# CH32X035 register map
Vendor: WCH Ltd.; File version: 1.0
Registers are 32-bit, read-write, reset 0x0 unless marked. A register's access mark holds for its fields unless they carry their own. Offsets are from the block's base; [hi:lo] are bit positions; lines under a group give offsets from that group; {n}, {i} and the like mark numbered series.

## SPI1 — Serial peripheral interface
Base 0x40013000
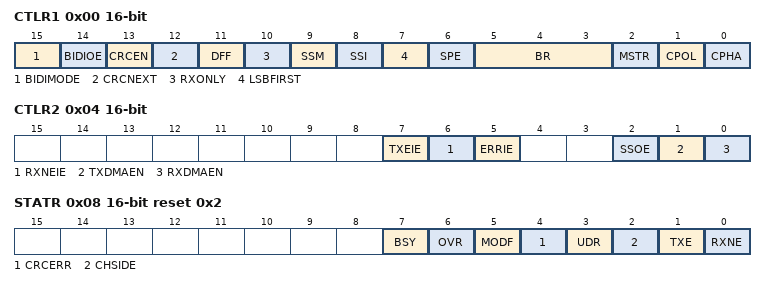
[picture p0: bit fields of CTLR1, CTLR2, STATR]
0x00 CTLR1 16-bit — control register 1
  [15] BIDIMODE — Bidirectional data mode enable
  [14] BIDIOE — Output enable in bidirectional mode
  [13] CRCEN — Hardware CRC calculation enable
  [12] CRCNEXT — CRC transfer next
  [11] DFF — Data frame format
  [10] RXONLY — Receive only
  [9] SSM — Software slave management
  [8] SSI — Internal slave select
  [7] LSBFIRST — Frame format
  [6] SPE — SPI enable
  [5:3] BR — Baud rate control
  [2] MSTR — Master selection
  [1] CPOL — Clock polarity
  [0] CPHA — Clock phase
0x04 CTLR2 16-bit — control register 2
  [7] TXEIE — Tx buffer empty interrupt enable
  [6] RXNEIE — RX buffer not empty interrupt enable
  [5] ERRIE — Error interrupt enable
  [2] SSOE — SS output enable
  [1] TXDMAEN — Tx buffer DMA enable
  [0] RXDMAEN — Rx buffer DMA enable
0x08 STATR 16-bit access per field reset 0x2 — status register
  [7] BSY ro — Busy flag
  [6] OVR rw — Overrun flag
  [5] MODF ro — Mode fault
  [4] CRCERR rw — CRC error flag
  [3] UDR ro — Underrun flag
  [2] CHSIDE ro — Channel side
  [1] TXE ro — Transmit buffer empty
  [0] RXNE ro — Receive buffer not empty
0x0C DATAR 16-bit — data register
  [15:0] DR — Data register
0x10 CRCR 16-bit reset 0x7 — CRCR polynomial register
  [15:0] CRCPOLY — CRC polynomial register
0x14 RCRCR 16-bit ro — RX CRC register
  [15:0] RXCRC
0x18 TCRCR 16-bit ro — send CRC register
  [15:0] TXCRC
0x24 HSCR 16-bit wo — high speed control register
  [0] HSRXEN — High speed mode read enable

## USART1 — Universal synchronous asynchronous receiver transmitter
Base 0x40013800
Same registers: USART2 0x40004400, USART3 0x40004800, USART4 0x40004C00
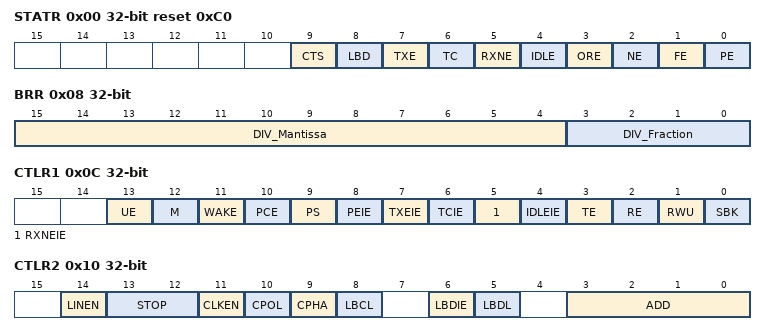
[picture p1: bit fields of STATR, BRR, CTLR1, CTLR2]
0x00 STATR access per field reset 0xC0 — Status register
  [9] CTS rw — CTS flag
  [8] LBD rw — LIN break detection flag
  [7] TXE ro — Transmit data register empty
  [6] TC rw — Transmission complete
  [5] RXNE rw — Read data register not empty
  [4] IDLE ro — IDLE line detected
  [3] ORE ro — Overrun error
  [2] NE ro — Noise error flag
  [1] FE ro — Framing error
  [0] PE ro — Parity error
0x04 DATAR — Data register
  [8:0] DR — Data value
0x08 BRR — Baud rate register
  [15:4] DIV_Mantissa — mantissa of USARTDIV
  [3:0] DIV_Fraction — fraction of USARTDIV
0x0C CTLR1 — Control register 1
  [13] UE — USART enable
  [12] M — Word length
  [11] WAKE — Wakeup method
  [10] PCE — Parity control enable
  [9] PS — Parity selection
  [8] PEIE — PE interrupt enable
  [7] TXEIE — TXE interrupt enable
  [6] TCIE — Transmission complete interrupt enable
  [5] RXNEIE — RXNE interrupt enable
  [4] IDLEIE — IDLE interrupt enable
  [3] TE — Transmitter enable
  [2] RE — Receiver enable
  [1] RWU — Receiver wakeup
  [0] SBK — Send break
0x10 CTLR2 — Control register 2
  [14] LINEN — LIN mode enable
  [13:12] STOP — STOP bits
  [11] CLKEN — Clock enable
  [10] CPOL — Clock polarity
  [9] CPHA — Clock phase
  [8] LBCL — Last bit clock pulse
  [6] LBDIE — LIN break detection interrupt enable
  [5] LBDL — lin break detection length
  [3:0] ADD — Address of the USART node
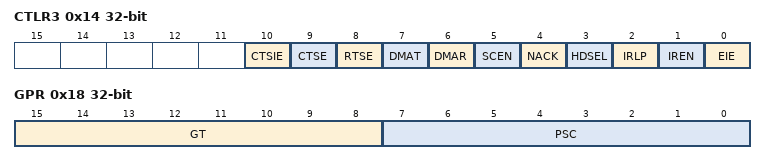
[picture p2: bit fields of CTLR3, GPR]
0x14 CTLR3 — Control register 3
  [10] CTSIE — CTS interrupt enable
  [9] CTSE — CTS enable
  [8] RTSE — RTS enable
  [7] DMAT — DMA enable transmitter
  [6] DMAR — DMA enable receiver
  [5] SCEN — Smartcard mode enable
  [4] NACK — Smartcard NACK enable
  [3] HDSEL — Half-duplex selection
  [2] IRLP — IrDA low-power
  [1] IREN — IrDA mode enable
  [0] EIE — Error interrupt enable
0x18 GPR — Guard time and prescaler register
  [15:8] GT — Guard time value
  [7:0] PSC — Prescaler value

## ADC — Analog to digital converter
Base 0x40012400
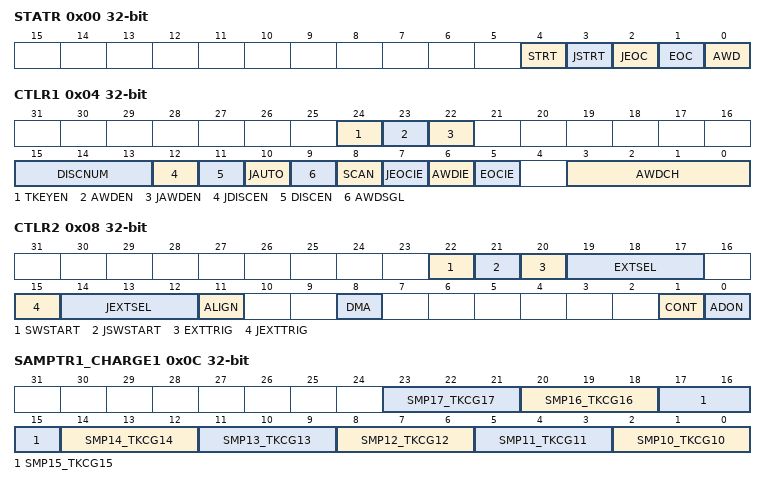
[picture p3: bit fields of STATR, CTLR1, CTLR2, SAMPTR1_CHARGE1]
0x00 STATR — status register
  [4] STRT — Regular channel start flag
  [3] JSTRT — Injected channel start flag
  [2] JEOC — Injected channel end of conversion
  [1] EOC — Regular channel end of conversion
  [0] AWD — Analog watchdog flag
0x04 CTLR1 — control register 1
  [24] TKEYEN — TKEY enable, including TKEY_F and TKEY_V
  [23] AWDEN — Analog watchdog enable on regular channels
  [22] JAWDEN — Analog watchdog enable on injected channels
  [15:13] DISCNUM — Discontinuous mode channel count
  [12] JDISCEN — Discontinuous mode on injected channels
  [11] DISCEN — Discontinuous mode on regular channels
  [10] JAUTO — Automatic injected group conversion
  [9] AWDSGL — Enable the watchdog on a single channel in scan mode
  [8] SCAN — Scan mode enable
  [7] JEOCIE — Interrupt enable for injected channels
  [6] AWDIE — Analog watchdog interrupt enable
  [5] EOCIE — Interrupt enable for EOC
  [3:0] AWDCH — Analog watchdog channel select bits
0x08 CTLR2 — control register 2
  [22] SWSTART — Start conversion of regular channels
  [21] JSWSTART — Start conversion of injected channels
  [20] EXTTRIG — External trigger conversion mode for regular channels
  [19:17] EXTSEL — External event select for regular group
  [15] JEXTTRIG — External trigger conversion mode for injected channels
  [14:12] JEXTSEL — External event select for injected group
  [11] ALIGN — Data alignment
  [8] DMA — Direct memory access mode
  [1] CONT — Continuous conversion
  [0] ADON — A/D converter ON / OFF
0x0C SAMPTR1_CHARGE1 — sample time register 1/TKEYx_CHARGE1
  [3n-28:3n-30] SMP{n}_TKCG{n} (n=10..17) — Channel {n} sample time selection
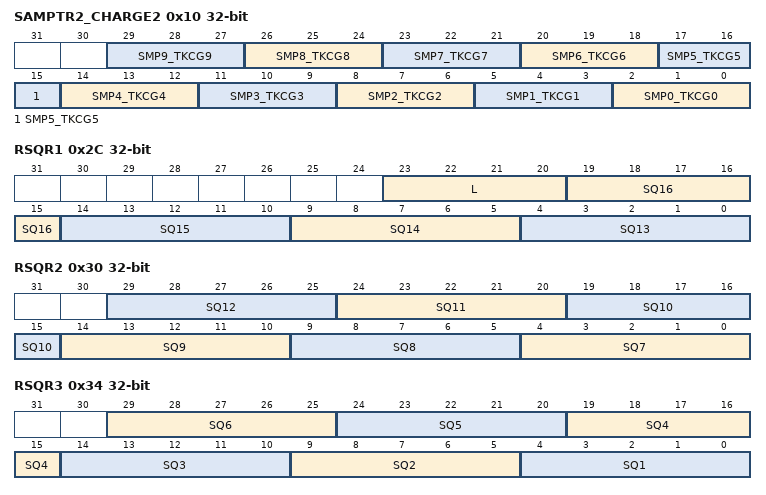
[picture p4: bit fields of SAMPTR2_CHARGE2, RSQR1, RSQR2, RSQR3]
0x10 SAMPTR2_CHARGE2 — sample time register 2/TKEYx_CHARGE2
  [3n+2:3n] SMP{n}_TKCG{n} (n=0..9) — Channel {n} sample time selection
{0x10+4i} IOFR{i} (i=1..4) — injected channel data offset register x
  [11:0] JOFFSET{i} — Data offset for injected channel x
0x24 WDHTR — watchdog higher threshold register
  [11:0] HT — Analog watchdog higher threshold
0x28 WDLTR — watchdog lower threshold register
  [11:0] LT — Analog watchdog lower threshold
0x2C RSQR1 — regular sequence register 1
  [23:20] L — Regular channel sequence length
  [5n-61:5n-65] SQ{n} (n=13..16) — {n}th conversion in regular sequence
0x30 RSQR2 — regular sequence register 2
  [5n-31:5n-35] SQ{n} (n=7..12) — {n}th conversion in regular sequence
0x34 RSQR3 — regular sequence register 3
  [29:25] SQ6 — 6th conversion in regular sequence
  [24:20] SQ5 — 5th conversion in regular sequence
  [19:15] SQ4 — 4th conversion in regular sequence
  [14:10] SQ3 — 3rd conversion in regular sequence
  [9:5] SQ2 — 2nd conversion in regular sequence
  [4:0] SQ1 — 1st conversion in regular sequence
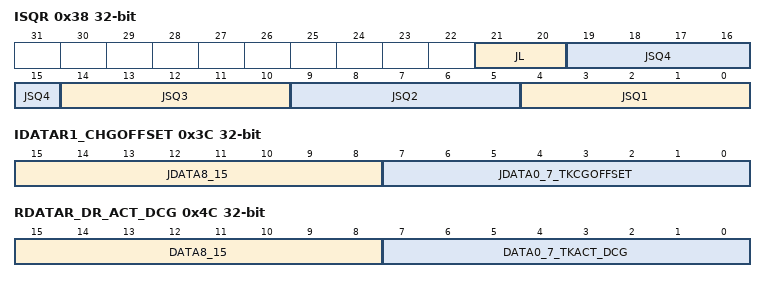
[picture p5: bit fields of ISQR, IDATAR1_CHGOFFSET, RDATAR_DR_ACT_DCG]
0x38 ISQR — injected sequence register
  [21:20] JL — Injected sequence length
  [19:15] JSQ4 — 4th conversion in injected sequence
  [14:10] JSQ3 — 3rd conversion in injected sequence
  [9:5] JSQ2 — 2nd conversion in injected sequence
  [4:0] JSQ1 — 1st conversion in injected sequence
0x3C IDATAR1_CHGOFFSET ro — injected data register x_Charge data offset for injected channel x/TKEYx_CHGOFFSET
  [15:8] JDATA8_15 — Injected data
  [7:0] JDATA0_7_TKCGOFFSET — Injected data_Touch key charge data offset for injected channel x
{0x38+4i} IDATAR{i} ro (i=2..4) — injected data register x
  [15:0] JDATA — Injected data
0x4C RDATAR_DR_ACT_DCG — regular data register_start and discharge time register/TKEYx_DR/TKEYx_ACT_DCG
  [15:8] DATA8_15 — Regular data
  [7:0] DATA0_7_TKACT_DCG — Regular data_Touch key start and discharge time register
0x50 CTLR3 — ADC control register 3
  [3:0] CLK_DIV — Clock divider
